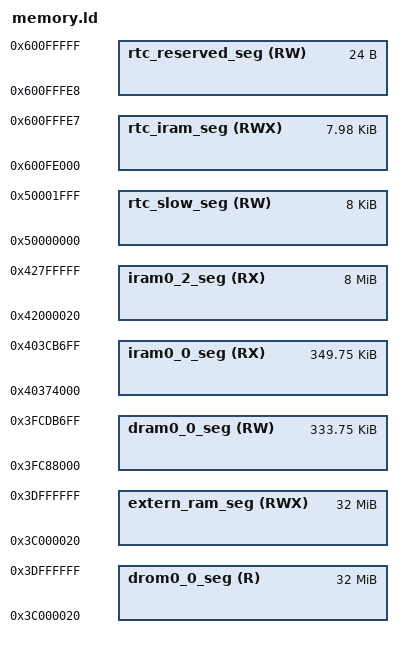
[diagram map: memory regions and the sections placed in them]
/* Карта памяти приложения. Наша, а не сгенерированная IDF.
 *
 * ЗАЧЕМ СВОЯ.
 *
 * До этого файла карту памяти задавал IDF: он подставлял в свой шаблон числа из
 * sdkconfig и складывал результат в .pio/build/<env>/memory.ld. Работало, но
 * означало, что границы памяти меняются у нас под ногами при обновлении
 * платформы, а увидеть их можно только в сборочном каталоге.
 *
 * Теперь границы записаны здесь явными числами, с объяснением откуда они, и
 * проверяются ASSERT'ами при каждой сборке.
 *
 * ЧТО ЗДЕСЬ СВОЁ, А ЧТО НЕТ.
 *
 * Свой - этот файл: области памяти (MEMORY) и несколько символов, которые от них
 * зависят. Чужой - `sections.ld`: там каталог из тысячи строк «какая секция
 * какого компонента IDF куда кладётся» (newlib, heap, драйверы). Он остаётся
 * чужим намеренно: переписать его - значит заодно переписать ожидания кода
 * IDF, который мы всё ещё используем (загрузчик, кэш, MMU, куча). Смысл имел бы
 * только вместе с отказом от старта IDF - это отдельная работа, не A0.
 *
 * ОТКУДА ЧИСЛА.
 *
 * ESP32-S3, 512 КБ SRAM. Адреса из технического описания, верхняя граница IRAM
 * (0x403CB700) - из линкер-скрипта загрузчика: выше начинается память, которую
 * занимает сам загрузчик второй ступени.
 *
 *   IRAM (исполнение)  0x40370000 .. 0x403CB700
 *   DRAM (данные)      0x3FC88000 .. 0x3FCDB700
 *   Внешняя flash (исполнение) 0x42000020 ..
 *   Внешняя flash (данные)     0x3C000020 ..
 *
 * IRAM и DRAM - одна и та же физическая память, видимая с двух сторон:
 * 0x40378000 и 0x3FC88000 - это один и тот же байт. Отсюда одинаковые размеры
 * областей (0x53700): сколько отдано под код, столько же недоступно под данные.
 *
 * Начало IRAM сдвинуто на 0x4000: первые 16 КБ занимает кэш инструкций
 * (CONFIG_ESP32S3_INSTRUCTION_CACHE_SIZE=0x4000). Начало DRAM не сдвигается -
 * кэш данных растёт вниз от 0x3FD00000 и в статической раскладке не участвует.
 *
 * ЧТО ПЕРЕПРОВЕРИТЬ ПОСЛЕ ОБНОВЛЕНИЯ ПЛАТФОРМЫ.
 *
 *  1. Размер кэша инструкций: если CONFIG_ESP32S3_INSTRUCTION_CACHE_SIZE станет
 *     другим, сдвинется начало IRAM и размер областей.
 *  2. Верхнюю границу 0x403CB700 - по линкер-скрипту загрузчика.
 *  3. CONFIG_BOOTLOADER_RESERVE_RTC_SIZE: здесь он равен нулю (см. RTC ниже).
 *
 * Ошибка в этих числах тихая: линкер соберёт образ, а плата не загрузится или
 * затрёт чужую память. Поэтому числа проверяются ASSERT'ами внизу - они ловят
 * расхождение с физической памятью, но не заменяют чтения лога загрузчика.
 */

/* Числа вынесены в символы, а не в #define: этот файл не проходит через
 * препроцессор C (PlatformIO отдаёт его линкеру как есть). Присваивание вне
 * SECTIONS создаёт абсолютный символ, и его можно использовать в MEMORY. */

/* Смещение, на котором сходятся два вида на одну память. */
DIRAM_I_START = 0x40378000;
DIRAM_D_START = 0x3FC88000;

/* Верхняя граница статической памяти. Дальше - загрузчик второй ступени. */
SRAM_END = 0x403CB700;

/* Размер блока, общего для кода и данных. */
DIRAM_SIZE = SRAM_END - (DIRAM_I_START - DIRAM_D_START) - DIRAM_D_START;

/* Кэш инструкций: занимает начало IRAM. */
ICACHE_SIZE = 0x4000;

MEMORY
{
    /* Код, который обязан работать без кэша: векторы, обработчики прерываний,
     * аварийный стек - всё, что нужно до того, как что-то вообще заработает. */
    iram0_0_seg (RX) :  org = 0x40370000 + ICACHE_SIZE,
                        len = DIRAM_SIZE + 0x8000 - ICACHE_SIZE

    /* Код во внешней flash, отображённый на адреса инструкций. Смещение 0x20 -
     * удобство формата образа: заголовок файла 0x18 байт плюс заголовок
     * сегмента 0x08, и тогда (адрес в файле % 64 КБ) совпадает с (адрес в
     * памяти % 64 КБ), как требует MMU кэша. */
    iram0_2_seg (RX) :  org = 0x42000020, len = 0x800000 - 0x20

    /* Данные, которые меняются: .data, .bss, стеки, куча. */
    dram0_0_seg (RW) :  org = DIRAM_D_START, len = DIRAM_SIZE

    /* Постоянные данные во внешней flash: строки, таблицы, этот же текст. */
    drom0_0_seg (R) :   org = 0x3C000020, len = 0x2000000 - 0x20

    /* RTC-память: переживает программный сброс и глубокий сон. Верхние 24 байта
     * зарезервированы за IDF под счётчик RTC-таймера - их не трогаем, иначе
     * после пробуждения время уедет. */
    rtc_iram_seg (RWX) :     org = 0x600FE000, len = 0x2000 - 24
    rtc_reserved_seg (RW) :  org = 0x600FE000 + 0x2000 - 24, len = 24

    /* Медленная RTC-память. Тот же адрес для данных и для кода. */
    rtc_slow_seg (RW) : org = 0x50000000, len = 0x2000

    /* Внешняя PSRAM. На этой плате её нет, но sections.ld ожидает область с
     * таким именем: он кладёт туда пустую заглушку, чтобы области не
     * пересекались по адресам. */
    extern_ram_seg (RWX) : org = 0x3C000020, len = 0x2000000 - 0x20
}

/* Начало области, общей для кода и данных, со стороны инструкций. */
_diram_i_start = DIRAM_I_START;

/* Куча: от конца статических данных до символической верхней границы. Начало
 * считает sections.ld (_heap_low_start) - оно зависит от того, где кончился
 * .bss. Верхняя граница 0x40000000 - не конец годной памяти, а число, которое
 * IDF объявляет для configTOTAL_HEAP_SIZE у FreeRTOS; реальный размер областей
 * для кучи определяет heap_caps_init по описанию SoC. */
_heap_start = _heap_low_start;
_heap_end = 0x40000000;

/* Имена, которых ждёт sections.ld: он не знает, какая из областей выбрана, и
 * обращается к роли, а не к имени. */
REGION_ALIAS("rtc_data_seg", rtc_iram_seg);
REGION_ALIAS("rtc_data_location", rtc_slow_seg);
REGION_ALIAS("default_code_seg", iram0_2_seg);
REGION_ALIAS("default_rodata_seg", drom0_0_seg);

/* Постоянные данные из flash обязаны начинаться с первого байта области: кэш
 * отображает flash страницами по 64 КБ, и первая страница образа должна
 * совпадать с началом области. sections.ld кладёт туда заглушку
 * .flash_rodata_dummy - проверяем, что она действительно попала в начало. */
ASSERT(_flash_rodata_dummy_start == ORIGIN(default_rodata_seg),
       "Постоянные данные не в начале области drom0_0_seg: сломается отображение flash в кэш.")

/* Самопроверка чисел выше. Сравнение идёт с литералами, а не с теми же
 * символами: ASSERT(что-то == SRAM_END) выполняется всегда, потому что все
 * размеры считаются из SRAM_END. Смысл проверки - поймать правку символа,
 * после которой области разъедутся с физической памятью. */
ASSERT(ORIGIN(iram0_0_seg) == 0x40374000,
       "Начало iram0_0_seg сдвинулось: проверьте ICACHE_SIZE (кэш инструкций) - 0x4000.")
ASSERT(ORIGIN(iram0_0_seg) + LENGTH(iram0_0_seg) == 0x403CB700,
       "iram0_0_seg кончается не там, где кончается статическая IRAM (0x403CB700).")
ASSERT(ORIGIN(dram0_0_seg) == 0x3FC88000,
       "Начало dram0_0_seg сдвинулось: проверьте DIRAM_D_START.")
ASSERT(ORIGIN(dram0_0_seg) + LENGTH(dram0_0_seg) == 0x3FCDB700,
       "dram0_0_seg кончается не там, где кончается статическая DRAM (0x3FCDB700).")
